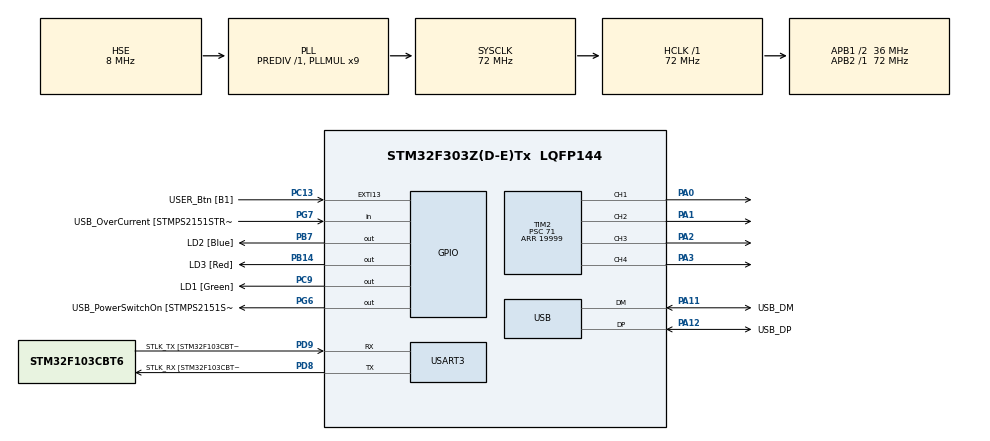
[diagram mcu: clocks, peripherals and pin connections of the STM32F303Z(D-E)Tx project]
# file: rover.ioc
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Mcu.Family=STM32F3
Mcu.Name=STM32F303Z(D-E)Tx
Mcu.Package=LQFP144
NVIC.PriorityGroup=NVIC_PRIORITYGROUP_4
NVIC.USB_LP_CAN_RX0_IRQn=true\:0\:0\:false\:false\:true\:true
PA0.Signal=S_TIM2_CH1_ETR
PA1.Signal=S_TIM2_CH2
PA11.GPIO_Label=USB_DM
PA11.Mode=Device
PA11.Signal=USB_DM
PA12.GPIO_Label=USB_DP
PA12.Mode=Device
PA12.Signal=USB_DP
PA13.GPIO_Label=TMS
PA13.Mode=Serial_Wire
PA13.Signal=SYS_JTMS-SWDIO
PA14.GPIO_Label=TCK
PA14.Mode=Serial_Wire
PA14.Signal=SYS_JTCK-SWCLK
PA2.Signal=S_TIM2_CH3
PA3.Signal=S_TIM2_CH4
PB14.GPIO_Label=LD3 [Red]
PB14.Signal=GPIO_Output
PB3.GPIO_Label=SWO
PB3.Signal=SYS_JTDO-TRACESWO
PB7.GPIO_Label=LD2 [Blue]
PB7.Signal=GPIO_Output
PC13.GPIO_Label=USER_Btn [B1]
PC13.Signal=GPXTI13
PC14-OSC32_IN.Mode=LSE-External-Oscillator
PC14-OSC32_IN.Signal=RCC_OSC32_IN
PC15-OSC32_OUT.Mode=LSE-External-Oscillator
PC15-OSC32_OUT.Signal=RCC_OSC32_OUT
PC9.GPIO_Label=LD1 [Green]
PC9.Signal=GPIO_Output
PD8.GPIO_Label=STLK_RX [STM32F103CBT6_PA3]
PD8.Mode=Asynchronous
PD8.Signal=USART3_TX
PD9.GPIO_Label=STLK_TX [STM32F103CBT6_PA2]
PD9.Mode=Asynchronous
PD9.Signal=USART3_RX
PF0-OSC_IN.GPIO_Label=MCO [STM32F103CBT6_PA8]
PF0-OSC_IN.Mode=HSE-External-Clock-Source
PF0-OSC_IN.Signal=RCC_OSC_IN
PG6.GPIO_Label=USB_PowerSwitchOn [STMPS2151STR_EN]
PG6.Signal=GPIO_Output
PG7.GPIO_Label=USB_OverCurrent [STMPS2151STR_FAULT]
PG7.Signal=GPIO_Input
ProjectManager.HeapSize=0x200
ProjectManager.StackSize=0x400
ProjectManager.TargetToolchain=Makefile
RCC.AHBFreq_Value=72000000
RCC.APB1CLKDivider=RCC_HCLK_DIV2
RCC.APB1Freq_Value=36000000
RCC.APB1TimFreq_Value=72000000
RCC.APB2Freq_Value=72000000
RCC.APB2TimFreq_Value=72000000
RCC.CortexFreq_Value=72000000
RCC.HCLKFreq_Value=72000000
RCC.HSE_VALUE=8000000
RCC.HSI_VALUE=8000000
RCC.PLLMUL=RCC_PLL_MUL9
RCC.PRESCALERUSB=RCC_USBCLKSOURCE_PLL_DIV1_5
RCC.SYSCLKFreq_VALUE=72000000
RCC.SYSCLKSourceVirtual=RCC_SYSCLKSOURCE_PLLCLK
RCC.USBFreq_Value=48000000
SH.S_TIM2_CH1_ETR.0=TIM2_CH1,PWM Generation1 CH1
SH.S_TIM2_CH2.0=TIM2_CH2,PWM Generation2 CH2
SH.S_TIM2_CH3.0=TIM2_CH3,PWM Generation3 CH3
SH.S_TIM2_CH4.0=TIM2_CH4,PWM Generation4 CH4
TIM2.Channel-PWM\ Generation1\ CH1=TIM_CHANNEL_1
TIM2.Channel-PWM\ Generation2\ CH2=TIM_CHANNEL_2
TIM2.Channel-PWM\ Generation3\ CH3=TIM_CHANNEL_3
TIM2.Channel-PWM\ Generation4\ CH4=TIM_CHANNEL_4
TIM2.Period=19999
TIM2.Prescaler=71
TIM2.Pulse-PWM\ Generation1\ CH1=1099
TIM2.Pulse-PWM\ Generation2\ CH2=1899
USART3.VirtualMode-Asynchronous=VM_ASYNC
VP_RTC_VS_RTC_Activate.Mode=RTC_Enabled
VP_TIM2_VS_ClockSourceINT.Mode=Internal
board=NUCLEO-F303ZE

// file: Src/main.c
/**
  ******************************************************************************
  * @file           : main.c
  * @brief          : Main program body
  ******************************************************************************
  ** This notice applies to any and all portions of this file
  * that are not between comment pairs USER CODE BEGIN and
  * USER CODE END. Other portions of this file, whether
  * inserted by the user or by software development tools
  * are owned by their respective copyright owners.
  *
  * COPYRIGHT(c) 2019 STMicroelectronics
  *
  * Redistribution and use in source and binary forms, with or without modification,
  * are permitted provided that the following conditions are met:
  *   1. Redistributions of source code must retain the above copyright notice,
  *      this list of conditions and the following disclaimer.
  *   2. Redistributions in binary form must reproduce the above copyright notice,
  *      this list of conditions and the following disclaimer in the documentation
  *      and/or other materials provided with the distribution.
  *   3. Neither the name of STMicroelectronics nor the names of its contributors
  *      may be used to endorse or promote products derived from this software
  *      without specific prior written permission.
  *
  * THIS SOFTWARE IS PROVIDED BY THE COPYRIGHT HOLDERS AND CONTRIBUTORS "AS IS"
  * AND ANY EXPRESS OR IMPLIED WARRANTIES, INCLUDING, BUT NOT LIMITED TO, THE
  * IMPLIED WARRANTIES OF MERCHANTABILITY AND FITNESS FOR A PARTICULAR PURPOSE ARE
  * DISCLAIMED. IN NO EVENT SHALL THE COPYRIGHT HOLDER OR CONTRIBUTORS BE LIABLE
  * FOR ANY DIRECT, INDIRECT, INCIDENTAL, SPECIAL, EXEMPLARY, OR CONSEQUENTIAL
  * DAMAGES (INCLUDING, BUT NOT LIMITED TO, PROCUREMENT OF SUBSTITUTE GOODS OR
  * SERVICES; LOSS OF USE, DATA, OR PROFITS; OR BUSINESS INTERRUPTION) HOWEVER
  * CAUSED AND ON ANY THEORY OF LIABILITY, WHETHER IN CONTRACT, STRICT LIABILITY,
  * OR TORT (INCLUDING NEGLIGENCE OR OTHERWISE) ARISING IN ANY WAY OUT OF THE USE
  * OF THIS SOFTWARE, EVEN IF ADVISED OF THE POSSIBILITY OF SUCH DAMAGE.
  *
  ******************************************************************************
  */
#include "main.h"
#include "stm32f3xx_hal.h"
#include "rtc.h"
#include "tim.h"
#include "usart.h"
#include "usb.h"
#include "gpio.h"

/* USER CODE BEGIN PV */
/* Private variables ---------------------------------------------------------*/

/* USER CODE END PV */

void SystemClock_Config(void);

/* USER CODE BEGIN PFP */
/* Private function prototypes -----------------------------------------------*/

/* USER CODE END PFP */

int main(void)
{

  /* MCU Configuration----------------------------------------------------------*/

  /* Reset of all peripherals, Initializes the Flash interface and the Systick. */
  HAL_Init();

  /* Configure the system clock */
  SystemClock_Config();

  /* Initialize all configured peripherals */
  MX_GPIO_Init();
  MX_RTC_Init();
  MX_USART3_UART_Init();
  MX_USB_PCD_Init();
  MX_TIM2_Init();

  /* Infinite loop */
  /* USER CODE BEGIN WHILE */

  HAL_TIM_PWM_Start(&htim2, TIM_CHANNEL_1);
  HAL_TIM_PWM_Start(&htim2, TIM_CHANNEL_2);

  while (1) {

  /* USER CODE END WHILE */

  }

}

void SystemClock_Config(void)
{

  RCC_OscInitTypeDef RCC_OscInitStruct;
  RCC_ClkInitTypeDef RCC_ClkInitStruct;
  RCC_PeriphCLKInitTypeDef PeriphClkInit;

    /**Initializes the CPU, AHB and APB busses clocks
    */
  RCC_OscInitStruct.OscillatorType = RCC_OSCILLATORTYPE_LSI|RCC_OSCILLATORTYPE_HSE;
  RCC_OscInitStruct.HSEState = RCC_HSE_BYPASS;
  RCC_OscInitStruct.HSIState = RCC_HSI_ON;
  RCC_OscInitStruct.LSIState = RCC_LSI_ON;
  RCC_OscInitStruct.PLL.PLLState = RCC_PLL_ON;
  RCC_OscInitStruct.PLL.PLLSource = RCC_PLLSOURCE_HSE;
  RCC_OscInitStruct.PLL.PLLMUL = RCC_PLL_MUL9;
  RCC_OscInitStruct.PLL.PREDIV = RCC_PREDIV_DIV1;
  if (HAL_RCC_OscConfig(&RCC_OscInitStruct) != HAL_OK)
  {
    _Error_Handler(__FILE__, __LINE__);
  }

    /**Initializes the CPU, AHB and APB busses clocks
    */
  RCC_ClkInitStruct.ClockType = RCC_CLOCKTYPE_HCLK|RCC_CLOCKTYPE_SYSCLK
                              |RCC_CLOCKTYPE_PCLK1|RCC_CLOCKTYPE_PCLK2;
  RCC_ClkInitStruct.SYSCLKSource = RCC_SYSCLKSOURCE_PLLCLK;
  RCC_ClkInitStruct.AHBCLKDivider = RCC_SYSCLK_DIV1;
  RCC_ClkInitStruct.APB1CLKDivider = RCC_HCLK_DIV2;
  RCC_ClkInitStruct.APB2CLKDivider = RCC_HCLK_DIV1;

  if (HAL_RCC_ClockConfig(&RCC_ClkInitStruct, FLASH_LATENCY_2) != HAL_OK)
  {
    _Error_Handler(__FILE__, __LINE__);
  }

  PeriphClkInit.PeriphClockSelection = RCC_PERIPHCLK_USB|RCC_PERIPHCLK_USART3
                              |RCC_PERIPHCLK_RTC|RCC_PERIPHCLK_TIM2;
  PeriphClkInit.Usart3ClockSelection = RCC_USART3CLKSOURCE_PCLK1;
  PeriphClkInit.RTCClockSelection = RCC_RTCCLKSOURCE_LSI;
  PeriphClkInit.USBClockSelection = RCC_USBCLKSOURCE_PLL_DIV1_5;
  PeriphClkInit.Tim2ClockSelection = RCC_TIM2CLK_HCLK;
  if (HAL_RCCEx_PeriphCLKConfig(&PeriphClkInit) != HAL_OK)
  {
    _Error_Handler(__FILE__, __LINE__);
  }

    /**Configure the Systick interrupt time
    */
  HAL_SYSTICK_Config(HAL_RCC_GetHCLKFreq()/1000);

    /**Configure the Systick
    */
  HAL_SYSTICK_CLKSourceConfig(SYSTICK_CLKSOURCE_HCLK);

  /* SysTick_IRQn interrupt configuration */
  HAL_NVIC_SetPriority(SysTick_IRQn, 0, 0);
}

void _Error_Handler(char *file, int line)
{
  while (1) {
  }
}

#ifdef  USE_FULL_ASSERT
/**
  * @brief  Reports the name of the source file and the source line number
  *         where the assert_param error has occurred.
  * @param  file: pointer to the source file name
  * @param  line: assert_param error line source number
  * @retval None
  */
void assert_failed(uint8_t* file, uint32_t line)
{
  /* USER CODE BEGIN 6 */
  /* User can add his own implementation to report the file name and line
     number,
     tex: printf("Wrong parameters value: file %s on line %d\r\n", file, line)
   */
  /* USER CODE END 6 */
}
#endif /* USE_FULL_ASSERT */

/************************ (C) COPYRIGHT STMicroelectronics *****END OF FILE****/
